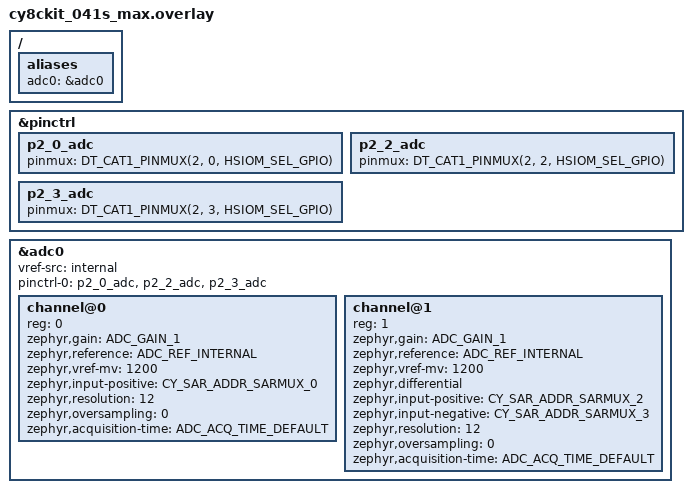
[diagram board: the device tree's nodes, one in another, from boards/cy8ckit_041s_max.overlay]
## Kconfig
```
# Copyright (c) 2024 Centro de Inovacao EDGE.
# SPDX-License-Identifier: Apache-2.0

config SEQUENCE_SAMPLES
	int "Number of samples to be made on the sequence for each channel."
	default 5

config SEQUENCE_RESOLUTION
	int "Set the resolution of the sequence readings."
	default 12

config SEQUENCE_OVERSAMPLING
	int "Set the oversampling of the sequence readings."
	default 0

config SEQUENCE_32BITS_REGISTERS
	bool "ADC data sequences are on 32bits"
	default n

source "Kconfig.zephyr"
```

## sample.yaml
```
sample:
  name: ADC driver sequence sample
common:
  tags:
    - adc
  depends_on: adc
  filter: dt_alias_exists("adc0")
  harness: console
  timeout: 10
  harness_config:
    type: multi_line
    regex:
      - "ADC sequence reading \\[\\d+\\]:"
      - "- .+, channel \\d+, \\d+ sequence samples:"
      - "- - \\d+ (= \\d+mV)|(\\(value in mV not available\\))"
tests:
  sample.drivers.adc.adc_sequence:
    platform_allow:
      - cy8cproto_063_ble
      - cy8cproto_062_4343w
      - nrf52840dk/nrf52840
      - nrf5340dk/nrf5340/cpuapp
      - nrf54h20dk/nrf54h20/cpuapp
      - nrf54h20dk/nrf54h20/cpuppr
      - nrf54l15dk/nrf54l15/cpuapp
      - nrf54lm20dk/nrf54lm20a/cpuapp
      - nrf54lm20dk/nrf54lm20b/cpuapp
      - ophelia4ev/nrf54l15/cpuapp
      - ucans32k1sic
      - s32k148_evb
      - frdm_ke15z
      - frdm_mcxc242
      - frdm_mcxe247
      - siwx917_rb4342a
      - slwrb4180a
      - xg27_rb4194a
      - xg29_rb4412a
      - raytac_an54lq_db_15/nrf54l15/cpuapp
      - mck_ra4t1
    integration_platforms:
      - nrf52840dk/nrf52840
  sample.drivers.adc.adc_sequence.8bit:
    platform_allow:
      - nrf54h20dk/nrf54h20/cpuapp
      - nrf54h20dk/nrf54h20/cpuppr
      - nrf54l15dk/nrf54l15/cpuapp
      - nrf54lm20dk/nrf54lm20a/cpuapp
      - nrf54lm20dk/nrf54lm20b/cpuapp
    integration_platforms:
      - nrf54l15dk/nrf54l15/cpuapp
    extra_configs:
      - CONFIG_SEQUENCE_RESOLUTION=8
```

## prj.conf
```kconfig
CONFIG_ADC=y
```

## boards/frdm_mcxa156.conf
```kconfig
# Copyright 2025 NXP
# SPDX-License-Identifier: Apache-2.0

CONFIG_ADC_MCUX_LPADC_DMA_DRIVEN=y
```

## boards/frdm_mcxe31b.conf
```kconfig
# Copyright 2025 NXP
# SPDX-License-Identifier: Apache-2.0

CONFIG_ADC_NXP_SAR_ADC_INTERRUPT=y
CONFIG_SEQUENCE_RESOLUTION=15
```

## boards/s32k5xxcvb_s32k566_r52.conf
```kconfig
# Copyright 2025 NXP
# SPDX-License-Identifier: Apache-2.0

CONFIG_SEQUENCE_RESOLUTION=11
```

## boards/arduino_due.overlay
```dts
/*
 * Copyright (c) 2024 Centro de Inovacao EDGE
 *
 * SPDX-License-Identifier: Apache-2.0
 */

/ {
	aliases {
		adc0 = &adc0;
	};
};

&adc0 {
	#address-cells = <1>;
	#size-cells = <0>;
	status = "okay";

	pinctrl-0 = <&adc0_default>;
	pinctrl-names = "default";

	prescaler = <9>;
	startup-time = <64>;
	settling-time = <3>;
	tracking-time = <2>;

	/* External ADC(+) */
	channel@6 { // Connector A1
		reg = <6>;
		zephyr,gain = "ADC_GAIN_1";
		zephyr,reference = "ADC_REF_EXTERNAL0";
		zephyr,acquisition-time = <ADC_ACQ_TIME_DEFAULT>;
		zephyr,input-positive = <6>;
		zephyr,vref-mv = <3300>;
	};

	channel@7 { // Connector A0
		reg = <7>;
		zephyr,gain = "ADC_GAIN_1";
		zephyr,reference = "ADC_REF_EXTERNAL0";
		zephyr,acquisition-time = <ADC_ACQ_TIME_DEFAULT>;
		zephyr,input-positive = <7>;
		zephyr,vref-mv = <3300>;
	};
};
```

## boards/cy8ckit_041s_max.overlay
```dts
/*
 * Copyright (c) 2025 Infineon Technologies AG,
 * or an affiliate of Infineon Technologies AG.
 *
 * SPDX-License-Identifier: Apache-2.0
 */

/*
 * ADC Channel Configuration for adc_sequence Sample
 * This overlay configures multiple ADC channels for sequential sampling.
 *
 * Test Setup:
 * - Connect P2.0 to a test voltage (e.g., 3.3V or variable)
 * - Connect P2.2 and P2.3 for differential measurement
 * - Connect GND for reference
 */

#include <zephyr/dt-bindings/adc/adc.h>
#include <zephyr/dt-bindings/adc/infineon-sar.h>
#include <zephyr/dt-bindings/pinctrl/ifx_cat1-pinctrl.h>

/ {
	aliases {
		adc0 = &adc0;
	};
};

&pinctrl {
	p2_0_adc: p2_0_adc {
		pinmux = <DT_CAT1_PINMUX(2, 0, HSIOM_SEL_GPIO)>;
	};

	p2_2_adc: p2_2_adc {
		pinmux = <DT_CAT1_PINMUX(2, 2, HSIOM_SEL_GPIO)>;
	};

	p2_3_adc: p2_3_adc {
		pinmux = <DT_CAT1_PINMUX(2, 3, HSIOM_SEL_GPIO)>;
	};
};

&adc0 {
	status = "okay";
	vref-src = "internal"; /* Use internal 1.2V reference */
	pinctrl-0 = <&p2_0_adc &p2_2_adc &p2_3_adc>;
	pinctrl-names = "default";
	#address-cells = <1>;
	#size-cells = <0>;

	channel@0 {
		reg = <0>;
		zephyr,gain = "ADC_GAIN_1";
		zephyr,reference = "ADC_REF_INTERNAL";
		zephyr,vref-mv = <1200>;
		zephyr,input-positive = <CY_SAR_ADDR_SARMUX_0>;  /* P2.0 - SARMUX direct */
		zephyr,resolution = <12>;
		zephyr,oversampling = <0>;
		zephyr,acquisition-time = <ADC_ACQ_TIME_DEFAULT>;
	};

	channel@1 {
		reg = <1>;
		zephyr,gain = "ADC_GAIN_1";
		zephyr,reference = "ADC_REF_INTERNAL";
		zephyr,vref-mv = <1200>;
		zephyr,differential;
		zephyr,input-positive = <CY_SAR_ADDR_SARMUX_2>;  /* P2.2 */
		zephyr,input-negative = <CY_SAR_ADDR_SARMUX_3>;  /* P2.3 */
		zephyr,resolution = <12>;
		zephyr,oversampling = <0>;
		zephyr,acquisition-time = <ADC_ACQ_TIME_DEFAULT>;
	};
};
```

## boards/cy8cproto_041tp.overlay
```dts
/*
 * Copyright (c) 2025 Infineon Technologies AG,
 * or an affiliate of Infineon Technologies AG.
 *
 * SPDX-License-Identifier: Apache-2.0
 */

#include <zephyr/dt-bindings/adc/adc.h>
#include <zephyr/dt-bindings/adc/infineon-sar.h>
#include <zephyr/dt-bindings/pinctrl/ifx_cat1-pinctrl.h>

/ {
	aliases {
		adc0 = &adc0;
	};
};

&pinctrl {
	/* ADC Channel 0: P2.0 */
	p2_0_adc: p2_0_adc {
		pinmux = <DT_CAT1_PINMUX(2, 0, HSIOM_SEL_GPIO)>;
	};

	/* ADC Channel 1: P2.2 (V+) */
	p2_2_adc: p2_2_adc {
		pinmux = <DT_CAT1_PINMUX(2, 2, HSIOM_SEL_GPIO)>;
	};

	/* ADC Channel 1: P2.3 (V-) */
	p2_3_adc: p2_3_adc {
		pinmux = <DT_CAT1_PINMUX(2, 3, HSIOM_SEL_GPIO)>;
	};
};

&adc0 {
	status = "okay";
	clocks = <&peri_clk_div4>;
	pinctrl-0 = <&p2_0_adc &p2_2_adc &p2_3_adc>;
	pinctrl-names = "default";
	#address-cells = <1>;
	#size-cells = <0>;

	/* Channel 0: Single-ended on P2.0 */
	channel@0 {
		reg = <0>;
		zephyr,gain = "ADC_GAIN_1";
		zephyr,reference = "ADC_REF_INTERNAL";
		zephyr,input-positive = <CY_SAR_ADDR_SARMUX_0>;
		zephyr,resolution = <12>;
		zephyr,oversampling = <0>;
		zephyr,acquisition-time = <ADC_ACQ_TIME_DEFAULT>;
	};

	/* Channel 1: Differential on P2.2 (+) and P2.3 (-) */
	channel@1 {
		reg = <1>;
		zephyr,gain = "ADC_GAIN_1";
		zephyr,reference = "ADC_REF_INTERNAL";
		zephyr,differential;
		zephyr,input-positive = <CY_SAR_ADDR_SARMUX_2>;
		zephyr,input-negative = <CY_SAR_ADDR_SARMUX_3>;
		zephyr,resolution = <12>;
		zephyr,oversampling = <0>;
		zephyr,acquisition-time = <ADC_ACQ_TIME_DEFAULT>;
	};
};
```

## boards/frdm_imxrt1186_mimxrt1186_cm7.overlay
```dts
/*
 * Copyright 2026 NXP
 *
 * SPDX-License-Identifier: Apache-2.0
 */

#include <zephyr/dt-bindings/adc/adc.h>
#include <zephyr/dt-bindings/adc/mcux-lpadc.h>

/ {
	aliases {
		adc0 = &lpadc1;
	};
};

&lpadc1 {
	#address-cells = <1>;
	#size-cells = <0>;

	/* Channel 0: GPIO_AD_15 (ADC1_CH1B) via J51-2 */
	channel@0 {
		reg = <0>;
		zephyr,gain = "ADC_GAIN_1";
		zephyr,reference = "ADC_REF_EXTERNAL0";
		zephyr,vref-mv = <1800>;
		zephyr,acquisition-time = <ADC_ACQ_TIME_DEFAULT>;
		zephyr,resolution = <12>;
		zephyr,input-positive = <MCUX_LPADC_CH1B>;
	};

	/* Channel 1: GPIO_AD_16 (ADC1_CH0A) via J51-4, ensure J28 is in 2-3 position */
	channel@1 {
		reg = <1>;
		zephyr,gain = "ADC_GAIN_1";
		zephyr,reference = "ADC_REF_EXTERNAL0";
		zephyr,vref-mv = <1800>;
		zephyr,acquisition-time = <ADC_ACQ_TIME_DEFAULT>;
		zephyr,resolution = <12>;
		zephyr,input-positive = <MCUX_LPADC_CH0A>;
	};
};
```

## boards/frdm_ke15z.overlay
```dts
/*
 * SPDX-License-Identifier: Apache-2.0
 *
 * Copyright 2025 NXP
 */

/ {
	aliases {
		adc0 = &adc0;
	};
};

&adc0 {
	#address-cells = <1>;
	#size-cells = <0>;

	/*
	 * To use this sample:
	 * - Connect ADC0 SE0 signal to voltage between 0~3.3V (J4 pin 2)
	 */

	channel@0 {
		reg = <0>;
		zephyr,gain = "ADC_GAIN_1";
		zephyr,reference = "ADC_REF_INTERNAL";
		zephyr,vref-mv = <3300>;
		zephyr,acquisition-time = <ADC_ACQ_TIME_DEFAULT>;
		zephyr,resolution = <12>;
	};
};
```

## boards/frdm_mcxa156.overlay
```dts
/*
 * Copyright 2025 NXP
 *
 * SPDX-License-Identifier: Apache-2.0
 */

#include <zephyr/dt-bindings/adc/adc.h>
#include <zephyr/dt-bindings/adc/mcux-lpadc.h>

/ {
	aliases {
		adc0 = &lpadc0;
	};
};

&lpadc0 {
	#address-cells = <1>;
	#size-cells = <0>;

	channel@0 {
		reg = <0>;
		zephyr,gain = "ADC_GAIN_1";
		zephyr,reference = "ADC_REF_EXTERNAL0";
		zephyr,vref-mv = <3300>;
		zephyr,acquisition-time = <ADC_ACQ_TIME_DEFAULT>;
		zephyr,resolution = <16>;
		zephyr,input-positive = <MCUX_LPADC_CH24A>; /* Internal VSSA */
	};

	channel@1 {
		reg = <1>;
		zephyr,gain = "ADC_GAIN_1";
		zephyr,reference = "ADC_REF_EXTERNAL0";
		zephyr,vref-mv = <3300>;
		zephyr,acquisition-time = <ADC_ACQ_TIME_DEFAULT>;
		zephyr,resolution = <16>;
		zephyr,input-positive = <MCUX_LPADC_CH29A>; /* Internal VDDA/4 */
	};
};
```

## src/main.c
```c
/*
 * Copyright (c) 2024 Centro de Inovacao EDGE
 *
 * SPDX-License-Identifier: Apache-2.0
 */

#include <zephyr/drivers/adc.h>
#include <zephyr/kernel.h>

/* ADC node from the devicetree. */
#define ADC_NODE DT_ALIAS(adc0)

/* Auxiliary macro to obtain channel vref, if available. */
#define CHANNEL_VREF(node_id) DT_PROP_OR(node_id, zephyr_vref_mv, 0)

/* Data of ADC device specified in devicetree. */
static const struct device *adc = DEVICE_DT_GET(ADC_NODE);

/* Data array of ADC channels for the specified ADC. */
static const struct adc_channel_cfg channel_cfgs[] = {
	DT_FOREACH_CHILD_SEP(ADC_NODE, ADC_CHANNEL_CFG_DT, (,))};

/* Data array of ADC channel voltage references. */
static uint32_t vrefs_mv[] = {DT_FOREACH_CHILD_SEP(ADC_NODE, CHANNEL_VREF, (,))};

/* Get the number of channels defined on the DTS. */
#define CHANNEL_COUNT ARRAY_SIZE(channel_cfgs)

int main(void)
{
	int err;
	uint32_t count = 0;
#ifdef CONFIG_SEQUENCE_32BITS_REGISTERS
	uint32_t channel_reading[CONFIG_SEQUENCE_SAMPLES][CHANNEL_COUNT];
#else
	uint16_t channel_reading[CONFIG_SEQUENCE_SAMPLES][CHANNEL_COUNT];
#endif

	/* Options for the sequence sampling. */
	const struct adc_sequence_options options = {
		.extra_samplings = CONFIG_SEQUENCE_SAMPLES - 1,
		.interval_us = 0,
	};

	/* Configure the sampling sequence to be made. */
	struct adc_sequence sequence = {
		.buffer = channel_reading,
		/* buffer size in bytes, not number of samples */
		.buffer_size = sizeof(channel_reading),
		.resolution = CONFIG_SEQUENCE_RESOLUTION,
		.oversampling = CONFIG_SEQUENCE_OVERSAMPLING,
		.options = &options,
	};

	if (!device_is_ready(adc)) {
		printf("ADC controller device %s not ready\n", adc->name);
		return 0;
	}

	/* Configure channels individually prior to sampling. */
	for (size_t i = 0U; i < CHANNEL_COUNT; i++) {
		sequence.channels |= BIT(channel_cfgs[i].channel_id);
		err = adc_channel_setup(adc, &channel_cfgs[i]);
		if (err < 0) {
			printf("Could not setup channel #%d (%d)\n", i, err);
			return 0;
		}
		if ((vrefs_mv[i] == 0) && (channel_cfgs[i].reference == ADC_REF_INTERNAL)) {
			vrefs_mv[i] = adc_ref_internal(adc);
		}
	}

#ifndef CONFIG_COVERAGE
	while (1) {
#else
	for (int k = 0; k < 10; k++) {
#endif
		printf("ADC sequence reading [%u]:\n", count++);
		k_msleep(1000);

		err = adc_read(adc, &sequence);
		if (err < 0) {
			printf("Could not read (%d)\n", err);
			continue;
		}

		for (size_t channel_index = 0U; channel_index < CHANNEL_COUNT; channel_index++) {
			int32_t val_mv;

			printf("- %s, channel %" PRId32 ", %" PRId32 " sequence samples:\n",
			       adc->name, channel_cfgs[channel_index].channel_id,
			       CONFIG_SEQUENCE_SAMPLES);
			for (size_t sample_index = 0U; sample_index < CONFIG_SEQUENCE_SAMPLES;
			     sample_index++) {
				uint8_t res = CONFIG_SEQUENCE_RESOLUTION;

				/*
				 * If using differential mode, the 16/32 bit value
				 * in the ADC sample buffer should be a signed 2's
				 * complement value.
				 * Also reduce the resolution by 1 for the conversion
				 */
				if (channel_cfgs[channel_index].differential) {
#ifdef CONFIG_SEQUENCE_32BITS_REGISTERS
					val_mv = (int32_t)
						channel_reading[sample_index][channel_index];
#else
					val_mv = (int32_t)((int16_t)channel_reading[sample_index]
										   [channel_index]);
#endif
					res -= 1;
				} else {
					val_mv = channel_reading[sample_index][channel_index];
				}
				printf("- - %" PRId32, val_mv);
				err = adc_raw_to_millivolts(vrefs_mv[channel_index],
							    channel_cfgs[channel_index].gain,
							    res, &val_mv);

				/* conversion to mV may not be supported, skip if not */
				if ((err < 0) || vrefs_mv[channel_index] == 0) {
					printf(" (value in mV not available)\n");
				} else {
					printf(" = %" PRId32 "mV\n", val_mv);
				}
			}
		}
	}

	return 0;
}
```
